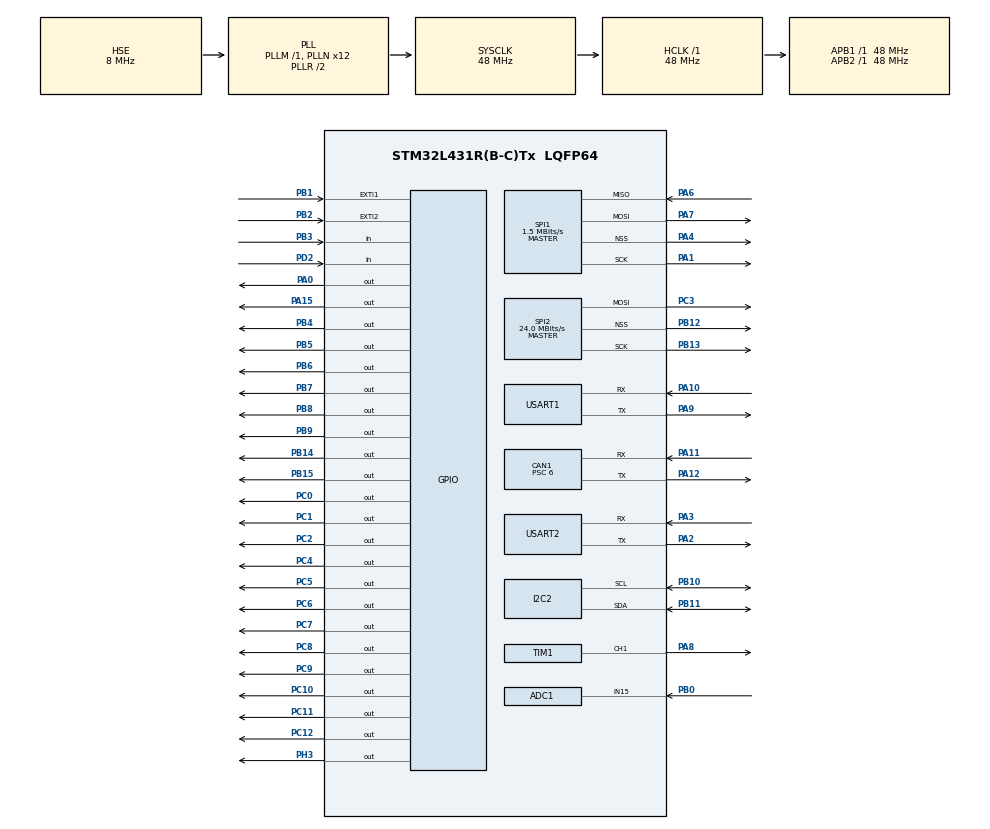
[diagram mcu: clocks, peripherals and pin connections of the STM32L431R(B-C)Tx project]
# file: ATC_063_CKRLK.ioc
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ADC1.Channel-1\#ChannelRegularConversion=ADC_CHANNEL_15
ADC1.NbrOfConversionFlag=1
ADC1.OffsetNumber-1\#ChannelRegularConversion=ADC_OFFSET_NONE
ADC1.Rank-1\#ChannelRegularConversion=1
ADC1.SamplingTime-1\#ChannelRegularConversion=ADC_SAMPLETIME_2CYCLES_5
ADC1.master=1
CAN1.BS1=CAN_BS1_13TQ
CAN1.BS2=CAN_BS2_2TQ
CAN1.CalculateBaudRate=500000
CAN1.CalculateTimeBit=2000
CAN1.CalculateTimeQuantum=125.0
CAN1.Prescaler=6
Dma.I2C2_RX.1.Direction=DMA_PERIPH_TO_MEMORY
Dma.I2C2_RX.1.Instance=DMA1_Channel5
Dma.I2C2_RX.1.MemDataAlignment=DMA_MDATAALIGN_BYTE
Dma.I2C2_RX.1.MemInc=DMA_MINC_ENABLE
Dma.I2C2_RX.1.Mode=DMA_NORMAL
Dma.I2C2_RX.1.PeriphDataAlignment=DMA_PDATAALIGN_BYTE
Dma.I2C2_RX.1.PeriphInc=DMA_PINC_DISABLE
Dma.I2C2_RX.1.Priority=DMA_PRIORITY_LOW
Dma.I2C2_TX.0.Direction=DMA_MEMORY_TO_PERIPH
Dma.I2C2_TX.0.Instance=DMA1_Channel4
Dma.I2C2_TX.0.MemDataAlignment=DMA_MDATAALIGN_BYTE
Dma.I2C2_TX.0.MemInc=DMA_MINC_ENABLE
Dma.I2C2_TX.0.Mode=DMA_NORMAL
Dma.I2C2_TX.0.PeriphDataAlignment=DMA_PDATAALIGN_BYTE
Dma.I2C2_TX.0.PeriphInc=DMA_PINC_DISABLE
Dma.I2C2_TX.0.Priority=DMA_PRIORITY_LOW
Dma.Request0=I2C2_TX
Dma.Request1=I2C2_RX
Dma.Request2=SPI1_RX
Dma.Request3=SPI1_TX
Dma.Request4=USART1_RX
Dma.Request5=USART1_TX
Dma.Request6=USART2_RX
Dma.Request7=USART2_TX
Dma.SPI1_RX.2.Direction=DMA_PERIPH_TO_MEMORY
Dma.SPI1_RX.2.Instance=DMA1_Channel2
Dma.SPI1_RX.2.MemDataAlignment=DMA_MDATAALIGN_BYTE
Dma.SPI1_RX.2.MemInc=DMA_MINC_ENABLE
Dma.SPI1_RX.2.Mode=DMA_NORMAL
Dma.SPI1_RX.2.PeriphDataAlignment=DMA_PDATAALIGN_BYTE
Dma.SPI1_RX.2.PeriphInc=DMA_PINC_DISABLE
Dma.SPI1_RX.2.Priority=DMA_PRIORITY_LOW
Dma.SPI1_TX.3.Direction=DMA_MEMORY_TO_PERIPH
Dma.SPI1_TX.3.Instance=DMA1_Channel3
Dma.SPI1_TX.3.MemDataAlignment=DMA_MDATAALIGN_BYTE
Dma.SPI1_TX.3.MemInc=DMA_MINC_ENABLE
Dma.SPI1_TX.3.Mode=DMA_NORMAL
Dma.SPI1_TX.3.PeriphDataAlignment=DMA_PDATAALIGN_BYTE
Dma.SPI1_TX.3.PeriphInc=DMA_PINC_DISABLE
Dma.SPI1_TX.3.Priority=DMA_PRIORITY_LOW
Dma.USART1_RX.4.Direction=DMA_PERIPH_TO_MEMORY
Dma.USART1_RX.4.Instance=DMA2_Channel7
Dma.USART1_RX.4.MemDataAlignment=DMA_MDATAALIGN_BYTE
Dma.USART1_RX.4.MemInc=DMA_MINC_ENABLE
Dma.USART1_RX.4.Mode=DMA_NORMAL
Dma.USART1_RX.4.PeriphDataAlignment=DMA_PDATAALIGN_BYTE
Dma.USART1_RX.4.PeriphInc=DMA_PINC_DISABLE
Dma.USART1_RX.4.Priority=DMA_PRIORITY_LOW
Dma.USART1_TX.5.Direction=DMA_MEMORY_TO_PERIPH
Dma.USART1_TX.5.Instance=DMA2_Channel6
Dma.USART1_TX.5.MemDataAlignment=DMA_MDATAALIGN_BYTE
Dma.USART1_TX.5.MemInc=DMA_MINC_ENABLE
Dma.USART1_TX.5.Mode=DMA_NORMAL
Dma.USART1_TX.5.PeriphDataAlignment=DMA_PDATAALIGN_BYTE
Dma.USART1_TX.5.PeriphInc=DMA_PINC_DISABLE
Dma.USART1_TX.5.Priority=DMA_PRIORITY_LOW
Dma.USART2_RX.6.Direction=DMA_PERIPH_TO_MEMORY
Dma.USART2_RX.6.Instance=DMA1_Channel6
Dma.USART2_RX.6.MemDataAlignment=DMA_MDATAALIGN_BYTE
Dma.USART2_RX.6.MemInc=DMA_MINC_ENABLE
Dma.USART2_RX.6.Mode=DMA_NORMAL
Dma.USART2_RX.6.PeriphDataAlignment=DMA_PDATAALIGN_BYTE
Dma.USART2_RX.6.PeriphInc=DMA_PINC_DISABLE
Dma.USART2_RX.6.Priority=DMA_PRIORITY_LOW
Dma.USART2_TX.7.Direction=DMA_MEMORY_TO_PERIPH
Dma.USART2_TX.7.Instance=DMA1_Channel7
Dma.USART2_TX.7.MemDataAlignment=DMA_MDATAALIGN_BYTE
Dma.USART2_TX.7.MemInc=DMA_MINC_ENABLE
Dma.USART2_TX.7.Mode=DMA_NORMAL
Dma.USART2_TX.7.PeriphDataAlignment=DMA_PDATAALIGN_BYTE
Dma.USART2_TX.7.PeriphInc=DMA_PINC_DISABLE
Dma.USART2_TX.7.Priority=DMA_PRIORITY_LOW
I2C2.Timing=0x20303E5D
LPTIM1.ClockPrescaler=LPTIM_PRESCALER_DIV128
Mcu.Family=STM32L4
Mcu.Name=STM32L431R(B-C)Tx
Mcu.Package=LQFP64
NVIC.CAN1_RX0_IRQn=true\:0\:0\:false\:false\:true\:true\:true\:true
NVIC.CAN1_SCE_IRQn=true\:0\:0\:false\:false\:true\:true\:true\:true
NVIC.DMA1_Channel2_IRQn=true\:0\:0\:false\:false\:true\:false\:true\:true
NVIC.DMA1_Channel3_IRQn=true\:0\:0\:false\:false\:true\:false\:true\:true
NVIC.DMA1_Channel4_IRQn=true\:0\:0\:false\:false\:true\:false\:true\:true
NVIC.DMA1_Channel5_IRQn=true\:0\:0\:false\:false\:true\:false\:true\:true
NVIC.DMA1_Channel6_IRQn=true\:0\:0\:false\:false\:true\:false\:true\:true
NVIC.DMA1_Channel7_IRQn=true\:0\:0\:false\:false\:true\:false\:true\:true
NVIC.DMA2_Channel6_IRQn=true\:0\:0\:false\:false\:true\:false\:true\:true
NVIC.DMA2_Channel7_IRQn=true\:0\:0\:false\:false\:true\:false\:true\:true
NVIC.EXTI1_IRQn=true\:0\:0\:false\:false\:true\:true\:true\:true
NVIC.EXTI2_IRQn=true\:0\:0\:false\:false\:true\:true\:true\:true
NVIC.I2C2_EV_IRQn=true\:0\:0\:false\:false\:true\:true\:true\:true
NVIC.LPTIM1_IRQn=true\:0\:0\:false\:false\:true\:true\:true\:true
NVIC.PriorityGroup=NVIC_PRIORITYGROUP_4
PA0.Signal=GPIO_Output
PA1.Mode=Full_Duplex_Master
PA1.Signal=SPI1_SCK
PA10.Mode=Asynchronous
PA10.Signal=USART1_RX
PA11.Mode=CAN_Activate
PA11.Signal=CAN1_RX
PA12.Mode=CAN_Activate
PA12.Signal=CAN1_TX
PA13\ (JTMS-SWDIO).Mode=Serial_Wire
PA13\ (JTMS-SWDIO).Signal=SYS_JTMS-SWDIO
PA14\ (JTCK-SWCLK).Mode=Serial_Wire
PA14\ (JTCK-SWCLK).Signal=SYS_JTCK-SWCLK
PA15\ (JTDI).Signal=GPIO_Output
PA2.Mode=Asynchronous
PA2.Signal=USART2_TX
PA3.Mode=Asynchronous
PA3.Signal=USART2_RX
PA4.Mode=NSS_Signal_Hard_Output
PA4.Signal=SPI1_NSS
PA5.Signal=ADCx_IN10
PA6.Mode=Full_Duplex_Master
PA6.Signal=SPI1_MISO
PA7.Mode=Full_Duplex_Master
PA7.Signal=SPI1_MOSI
PA8.Signal=S_TIM1_CH1
PA9.Mode=Asynchronous
PA9.Signal=USART1_TX
PB0.Signal=ADCx_IN15
PB1.Signal=GPXTI1
PB10.Mode=I2C
PB10.Signal=I2C2_SCL
PB11.Mode=I2C
PB11.Signal=I2C2_SDA
PB12.Mode=NSS_Signal_Hard_Output
PB12.Signal=SPI2_NSS
PB13.Mode=TX_Only_Simplex_Unidirect_Master
PB13.Signal=SPI2_SCK
PB14.Signal=GPIO_Output
PB15.Signal=GPIO_Output
PB2.Signal=GPXTI2
PB3\ (JTDO-TRACESWO).Signal=GPIO_Input
PB4\ (NJTRST).Signal=GPIO_Output
PB5.Signal=GPIO_Output
PB6.Signal=GPIO_Output
PB7.Signal=GPIO_Output
PB8.Signal=GPIO_Output
PB9.Signal=GPIO_Output
PC0.Signal=GPIO_Output
PC1.Signal=GPIO_Output
PC10.Signal=GPIO_Output
PC11.Signal=GPIO_Output
PC12.Signal=GPIO_Output
PC14-OSC32_IN\ (PC14).Mode=LSE-External-Oscillator
PC14-OSC32_IN\ (PC14).Signal=RCC_OSC32_IN
PC15-OSC32_OUT\ (PC15).Mode=LSE-External-Oscillator
PC15-OSC32_OUT\ (PC15).Signal=RCC_OSC32_OUT
PC2.Signal=GPIO_Output
PC3.Mode=TX_Only_Simplex_Unidirect_Master
PC3.Signal=SPI2_MOSI
PC4.Signal=GPIO_Output
PC5.Signal=GPIO_Output
PC6.Signal=GPIO_Output
PC7.Signal=GPIO_Output
PC8.Signal=GPIO_Output
PC9.Signal=GPIO_Output
PD2.Signal=GPIO_Input
PH0-OSC_IN\ (PH0).Mode=HSE-External-Oscillator
PH0-OSC_IN\ (PH0).Signal=RCC_OSC_IN
PH1-OSC_OUT\ (PH1).Mode=HSE-External-Oscillator
PH1-OSC_OUT\ (PH1).Signal=RCC_OSC_OUT
PH3-BOOT0.Signal=GPIO_Output
ProjectManager.HeapSize=0x200
ProjectManager.StackSize=0x400
ProjectManager.TargetToolchain=STM32CubeIDE
RCC.ADCFreq_Value=32000000
RCC.AHBFreq_Value=48000000
RCC.APB1Freq_Value=48000000
RCC.APB1TimFreq_Value=48000000
RCC.APB2Freq_Value=48000000
RCC.APB2TimFreq_Value=48000000
RCC.CortexFreq_Value=48000000
RCC.EnbaleCSS=true
RCC.HCLKFreq_Value=48000000
RCC.HSE_Timout=100
RCC.HSE_VALUE=8000000
RCC.HSI48_VALUE=48000000
RCC.HSI_VALUE=16000000
RCC.LSE_Timout=5000
RCC.MSI_VALUE=4000000
RCC.PLLN=12
RCC.PLLSourceVirtual=RCC_PLLSOURCE_HSE
RCC.SYSCLKFreq_VALUE=48000000
RCC.SYSCLKSource=RCC_SYSCLKSOURCE_PLLCLK
RCC.VCOOutputFreq_Value=96000000
SH.ADCx_IN10.0=ADC1_IN10
SH.ADCx_IN15.0=ADC1_IN15,IN15-Single-Ended
SH.S_TIM1_CH1.0=TIM1_CH1,Output Compare1 CH1
SPI1.BaudRatePrescaler=SPI_BAUDRATEPRESCALER_32
SPI1.CLKPhase=SPI_PHASE_2EDGE
SPI1.CalculateBaudRate=1.5 MBits/s
SPI1.DataSize=SPI_DATASIZE_8BIT
SPI1.Direction=SPI_DIRECTION_2LINES
SPI1.Mode=SPI_MODE_MASTER
SPI1.VirtualNSS=VM_NSSHARD
SPI1.VirtualType=VM_MASTER
SPI2.CLKPhase=SPI_PHASE_2EDGE
SPI2.CalculateBaudRate=24.0 MBits/s
SPI2.DataSize=SPI_DATASIZE_8BIT
SPI2.Direction=SPI_DIRECTION_2LINES
SPI2.Mode=SPI_MODE_MASTER
SPI2.VirtualNSS=VM_NSSHARD
SPI2.VirtualType=VM_MASTER
TIM1.Channel-Output\ Compare1\ CH1=TIM_CHANNEL_1
USART1.VirtualMode-Asynchronous=VM_ASYNC
USART2.VirtualMode-Asynchronous=VM_ASYNC
VP_ADC1_TempSens_Input.Mode=IN-TempSens
VP_ADC1_Vbat_Input.Mode=IN-Vbat
VP_CRC_VS_CRC.Mode=CRC_Activate
VP_LPTIM1_VS_LPTIM_counterModeInternalClock.Mode=Counts__internal_clock_event_00
VP_RTC_VS_RTC_Activate.Mode=RTC_Enabled
VP_RTC_VS_RTC_Calendar.Mode=RTC_Calendar
VP_TIM1_VS_ClockSourceINT.Mode=Internal
VP_TIM1_VS_ClockSourceITR.Mode=TriggerSource_ITR0
board=custom

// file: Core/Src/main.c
/* USER CODE BEGIN Header */
/**
  ******************************************************************************
  * @file           : main.c
  * @brief          : Main program body
  ******************************************************************************
  * @attention
  *
  * Copyright (c) 2022 STMicroelectronics.
  * All rights reserved.
  *
  * This software is licensed under terms that can be found in the LICENSE file
  * in the root directory of this software component.
  * If no LICENSE file comes with this software, it is provided AS-IS.
  *
  ******************************************************************************
  */
/* USER CODE END Header */
#include "main.h"

/* USER CODE BEGIN Includes */
#include "system_app/mainThread.h"
/* USER CODE END Includes */

ADC_HandleTypeDef hadc1;

CAN_HandleTypeDef hcan1;

CRC_HandleTypeDef hcrc;

I2C_HandleTypeDef hi2c2;
DMA_HandleTypeDef hdma_i2c2_tx;
DMA_HandleTypeDef hdma_i2c2_rx;

LPTIM_HandleTypeDef hlptim1;

RTC_HandleTypeDef hrtc;

SPI_HandleTypeDef hspi1;
SPI_HandleTypeDef hspi2;
DMA_HandleTypeDef hdma_spi1_rx;
DMA_HandleTypeDef hdma_spi1_tx;

TIM_HandleTypeDef htim1;

UART_HandleTypeDef huart1;
UART_HandleTypeDef huart2;
DMA_HandleTypeDef hdma_usart1_rx;
DMA_HandleTypeDef hdma_usart1_tx;
DMA_HandleTypeDef hdma_usart2_rx;
DMA_HandleTypeDef hdma_usart2_tx;

void SystemClock_Config(void);
static void MX_GPIO_Init(void);
static void MX_DMA_Init(void);
static void MX_RTC_Init(void);
static void MX_ADC1_Init(void);
static void MX_CAN1_Init(void);
static void MX_I2C2_Init(void);
static void MX_SPI1_Init(void);
static void MX_SPI2_Init(void);
static void MX_USART1_UART_Init(void);
static void MX_USART2_UART_Init(void);
static void MX_LPTIM1_Init(void);
static void MX_CRC_Init(void);
static void MX_TIM1_Init(void);

int main(void)
{

  /* MCU Configuration--------------------------------------------------------*/

  /* Reset of all peripherals, Initializes the Flash interface and the Systick. */
  HAL_Init();

  /* Configure the system clock */
  SystemClock_Config();

  /* Initialize all configured peripherals */
  MX_GPIO_Init();
  MX_DMA_Init();
  MX_RTC_Init();
  MX_ADC1_Init();
  MX_CAN1_Init();
  MX_I2C2_Init();
  MX_SPI1_Init();
  MX_SPI2_Init();
  MX_USART1_UART_Init();
  MX_USART2_UART_Init();
  MX_LPTIM1_Init();
  MX_CRC_Init();
  MX_TIM1_Init();
  /* USER CODE BEGIN 2 */
  MainThreadProcessInit();
  /* USER CODE END 2 */

  /* Infinite loop */
  while (1)
  {

  }
}

void SystemClock_Config(void)
{
  RCC_OscInitTypeDef RCC_OscInitStruct = {0};
  RCC_ClkInitTypeDef RCC_ClkInitStruct = {0};

  /** Configure the main internal regulator output voltage
  */
  if (HAL_PWREx_ControlVoltageScaling(PWR_REGULATOR_VOLTAGE_SCALE1) != HAL_OK)
  {
    Error_Handler();
  }
  /** Initializes the RCC Oscillators according to the specified parameters
  * in the RCC_OscInitTypeDef structure.
  */
  RCC_OscInitStruct.OscillatorType = RCC_OSCILLATORTYPE_LSI|RCC_OSCILLATORTYPE_HSE;
  RCC_OscInitStruct.HSEState = RCC_HSE_ON;
  RCC_OscInitStruct.LSIState = RCC_LSI_ON;
  RCC_OscInitStruct.PLL.PLLState = RCC_PLL_ON;
  RCC_OscInitStruct.PLL.PLLSource = RCC_PLLSOURCE_HSE;
  RCC_OscInitStruct.PLL.PLLM = 1;
  RCC_OscInitStruct.PLL.PLLN = 12;
  RCC_OscInitStruct.PLL.PLLP = RCC_PLLP_DIV7;
  RCC_OscInitStruct.PLL.PLLQ = RCC_PLLQ_DIV2;
  RCC_OscInitStruct.PLL.PLLR = RCC_PLLR_DIV2;
  if (HAL_RCC_OscConfig(&RCC_OscInitStruct) != HAL_OK)
  {
    Error_Handler();
  }
  /** Initializes the CPU, AHB and APB buses clocks
  */
  RCC_ClkInitStruct.ClockType = RCC_CLOCKTYPE_HCLK|RCC_CLOCKTYPE_SYSCLK
                              |RCC_CLOCKTYPE_PCLK1|RCC_CLOCKTYPE_PCLK2;
  RCC_ClkInitStruct.SYSCLKSource = RCC_SYSCLKSOURCE_PLLCLK;
  RCC_ClkInitStruct.AHBCLKDivider = RCC_SYSCLK_DIV1;
  RCC_ClkInitStruct.APB1CLKDivider = RCC_HCLK_DIV1;
  RCC_ClkInitStruct.APB2CLKDivider = RCC_HCLK_DIV1;

  if (HAL_RCC_ClockConfig(&RCC_ClkInitStruct, FLASH_LATENCY_2) != HAL_OK)
  {
    Error_Handler();
  }
  /** Enables the Clock Security System
  */
  HAL_RCC_EnableCSS();
}

static void MX_ADC1_Init(void)
{

  ADC_ChannelConfTypeDef sConfig = {0};

  /** Common config
  */
  hadc1.Instance = ADC1;
  hadc1.Init.ClockPrescaler = ADC_CLOCK_ASYNC_DIV1;
  hadc1.Init.Resolution = ADC_RESOLUTION_12B;
  hadc1.Init.DataAlign = ADC_DATAALIGN_RIGHT;
  hadc1.Init.ScanConvMode = ADC_SCAN_DISABLE;
  hadc1.Init.EOCSelection = ADC_EOC_SINGLE_CONV;
  hadc1.Init.LowPowerAutoWait = DISABLE;
  hadc1.Init.ContinuousConvMode = DISABLE;
  hadc1.Init.NbrOfConversion = 1;
  hadc1.Init.DiscontinuousConvMode = DISABLE;
  hadc1.Init.ExternalTrigConv = ADC_SOFTWARE_START;
  hadc1.Init.ExternalTrigConvEdge = ADC_EXTERNALTRIGCONVEDGE_NONE;
  hadc1.Init.DMAContinuousRequests = DISABLE;
  hadc1.Init.Overrun = ADC_OVR_DATA_PRESERVED;
  hadc1.Init.OversamplingMode = DISABLE;
  if (HAL_ADC_Init(&hadc1) != HAL_OK)
  {
    Error_Handler();
  }
  /** Configure Regular Channel
  */
  sConfig.Channel = ADC_CHANNEL_15;
  sConfig.Rank = ADC_REGULAR_RANK_1;
  sConfig.SamplingTime = ADC_SAMPLETIME_2CYCLES_5;
  sConfig.SingleDiff = ADC_SINGLE_ENDED;
  sConfig.OffsetNumber = ADC_OFFSET_NONE;
  sConfig.Offset = 0;
  if (HAL_ADC_ConfigChannel(&hadc1, &sConfig) != HAL_OK)
  {
    Error_Handler();
  }

}

static void MX_CAN1_Init(void)
{

  hcan1.Instance = CAN1;
  hcan1.Init.Prescaler = 6;
  hcan1.Init.Mode = CAN_MODE_NORMAL;
  hcan1.Init.SyncJumpWidth = CAN_SJW_1TQ;
  hcan1.Init.TimeSeg1 = CAN_BS1_13TQ;
  hcan1.Init.TimeSeg2 = CAN_BS2_2TQ;
  hcan1.Init.TimeTriggeredMode = DISABLE;
  hcan1.Init.AutoBusOff = DISABLE;
  hcan1.Init.AutoWakeUp = DISABLE;
  hcan1.Init.AutoRetransmission = DISABLE;
  hcan1.Init.ReceiveFifoLocked = DISABLE;
  hcan1.Init.TransmitFifoPriority = DISABLE;
  if (HAL_CAN_Init(&hcan1) != HAL_OK)
  {
    Error_Handler();
  }

}

static void MX_CRC_Init(void)
{

  hcrc.Instance = CRC;
  hcrc.Init.DefaultPolynomialUse = DEFAULT_POLYNOMIAL_ENABLE;
  hcrc.Init.DefaultInitValueUse = DEFAULT_INIT_VALUE_ENABLE;
  hcrc.Init.InputDataInversionMode = CRC_INPUTDATA_INVERSION_NONE;
  hcrc.Init.OutputDataInversionMode = CRC_OUTPUTDATA_INVERSION_DISABLE;
  hcrc.InputDataFormat = CRC_INPUTDATA_FORMAT_BYTES;
  if (HAL_CRC_Init(&hcrc) != HAL_OK)
  {
    Error_Handler();
  }

}

static void MX_I2C2_Init(void)
{

  hi2c2.Instance = I2C2;
  hi2c2.Init.Timing = 0x20303E5D;
  hi2c2.Init.OwnAddress1 = 0;
  hi2c2.Init.AddressingMode = I2C_ADDRESSINGMODE_7BIT;
  hi2c2.Init.DualAddressMode = I2C_DUALADDRESS_DISABLE;
  hi2c2.Init.OwnAddress2 = 0;
  hi2c2.Init.OwnAddress2Masks = I2C_OA2_NOMASK;
  hi2c2.Init.GeneralCallMode = I2C_GENERALCALL_DISABLE;
  hi2c2.Init.NoStretchMode = I2C_NOSTRETCH_DISABLE;
  if (HAL_I2C_Init(&hi2c2) != HAL_OK)
  {
    Error_Handler();
  }
  /** Configure Analogue filter
  */
  if (HAL_I2CEx_ConfigAnalogFilter(&hi2c2, I2C_ANALOGFILTER_ENABLE) != HAL_OK)
  {
    Error_Handler();
  }
  /** Configure Digital filter
  */
  if (HAL_I2CEx_ConfigDigitalFilter(&hi2c2, 0) != HAL_OK)
  {
    Error_Handler();
  }

}

static void MX_LPTIM1_Init(void)
{

  hlptim1.Instance = LPTIM1;
  hlptim1.Init.Clock.Source = LPTIM_CLOCKSOURCE_APBCLOCK_LPOSC;
  hlptim1.Init.Clock.Prescaler = LPTIM_PRESCALER_DIV128;
  hlptim1.Init.Trigger.Source = LPTIM_TRIGSOURCE_SOFTWARE;
  hlptim1.Init.OutputPolarity = LPTIM_OUTPUTPOLARITY_HIGH;
  hlptim1.Init.UpdateMode = LPTIM_UPDATE_IMMEDIATE;
  hlptim1.Init.CounterSource = LPTIM_COUNTERSOURCE_INTERNAL;
  hlptim1.Init.Input1Source = LPTIM_INPUT1SOURCE_GPIO;
  hlptim1.Init.Input2Source = LPTIM_INPUT2SOURCE_GPIO;
  if (HAL_LPTIM_Init(&hlptim1) != HAL_OK)
  {
    Error_Handler();
  }

}

static void MX_RTC_Init(void)
{

  RTC_TimeTypeDef sTime = {0};
  RTC_DateTypeDef sDate = {0};

  /** Initialize RTC Only
  */
  hrtc.Instance = RTC;
  hrtc.Init.HourFormat = RTC_HOURFORMAT_24;
  hrtc.Init.AsynchPrediv = 127;
  hrtc.Init.SynchPrediv = 255;
  hrtc.Init.OutPut = RTC_OUTPUT_DISABLE;
  hrtc.Init.OutPutRemap = RTC_OUTPUT_REMAP_NONE;
  hrtc.Init.OutPutPolarity = RTC_OUTPUT_POLARITY_HIGH;
  hrtc.Init.OutPutType = RTC_OUTPUT_TYPE_OPENDRAIN;
  if (HAL_RTC_Init(&hrtc) != HAL_OK)
  {
    Error_Handler();
  }

  /** Initialize RTC and set the Time and Date
  */
  sTime.Hours = 0x0;
  sTime.Minutes = 0x0;
  sTime.Seconds = 0x0;
  sTime.DayLightSaving = RTC_DAYLIGHTSAVING_NONE;
  sTime.StoreOperation = RTC_STOREOPERATION_RESET;
  if (HAL_RTC_SetTime(&hrtc, &sTime, RTC_FORMAT_BCD) != HAL_OK)
  {
    Error_Handler();
  }
  sDate.WeekDay = RTC_WEEKDAY_MONDAY;
  sDate.Month = RTC_MONTH_JANUARY;
  sDate.Date = 0x1;
  sDate.Year = 0x0;

  if (HAL_RTC_SetDate(&hrtc, &sDate, RTC_FORMAT_BCD) != HAL_OK)
  {
    Error_Handler();
  }

}

static void MX_SPI1_Init(void)
{

  /* SPI1 parameter configuration*/
  hspi1.Instance = SPI1;
  hspi1.Init.Mode = SPI_MODE_MASTER;
  hspi1.Init.Direction = SPI_DIRECTION_2LINES;
  hspi1.Init.DataSize = SPI_DATASIZE_8BIT;
  hspi1.Init.CLKPolarity = SPI_POLARITY_LOW;
  hspi1.Init.CLKPhase = SPI_PHASE_2EDGE;
  hspi1.Init.NSS = SPI_NSS_HARD_OUTPUT;
  hspi1.Init.BaudRatePrescaler = SPI_BAUDRATEPRESCALER_32;
  hspi1.Init.FirstBit = SPI_FIRSTBIT_MSB;
  hspi1.Init.TIMode = SPI_TIMODE_DISABLE;
  hspi1.Init.CRCCalculation = SPI_CRCCALCULATION_DISABLE;
  hspi1.Init.CRCPolynomial = 7;
  hspi1.Init.CRCLength = SPI_CRC_LENGTH_DATASIZE;
  hspi1.Init.NSSPMode = SPI_NSS_PULSE_DISABLE;
  if (HAL_SPI_Init(&hspi1) != HAL_OK)
  {
    Error_Handler();
  }

}

static void MX_SPI2_Init(void)
{

  /* SPI2 parameter configuration*/
  hspi2.Instance = SPI2;
  hspi2.Init.Mode = SPI_MODE_MASTER;
  hspi2.Init.Direction = SPI_DIRECTION_2LINES;
  hspi2.Init.DataSize = SPI_DATASIZE_8BIT;
  hspi2.Init.CLKPolarity = SPI_POLARITY_LOW;
  hspi2.Init.CLKPhase = SPI_PHASE_2EDGE;
  hspi2.Init.NSS = SPI_NSS_HARD_OUTPUT;
  hspi2.Init.BaudRatePrescaler = SPI_BAUDRATEPRESCALER_2;
  hspi2.Init.FirstBit = SPI_FIRSTBIT_MSB;
  hspi2.Init.TIMode = SPI_TIMODE_DISABLE;
  hspi2.Init.CRCCalculation = SPI_CRCCALCULATION_DISABLE;
  hspi2.Init.CRCPolynomial = 7;
  hspi2.Init.CRCLength = SPI_CRC_LENGTH_DATASIZE;
  hspi2.Init.NSSPMode = SPI_NSS_PULSE_DISABLE;
  if (HAL_SPI_Init(&hspi2) != HAL_OK)
  {
    Error_Handler();
  }

}

static void MX_TIM1_Init(void)
{

  TIM_ClockConfigTypeDef sClockSourceConfig = {0};
  TIM_SlaveConfigTypeDef sSlaveConfig = {0};
  TIM_MasterConfigTypeDef sMasterConfig = {0};
  TIM_OC_InitTypeDef sConfigOC = {0};
  TIM_BreakDeadTimeConfigTypeDef sBreakDeadTimeConfig = {0};

  htim1.Instance = TIM1;
  htim1.Init.Prescaler = 0;
  htim1.Init.CounterMode = TIM_COUNTERMODE_UP;
  htim1.Init.Period = 65535;
  htim1.Init.ClockDivision = TIM_CLOCKDIVISION_DIV1;
  htim1.Init.RepetitionCounter = 0;
  htim1.Init.AutoReloadPreload = TIM_AUTORELOAD_PRELOAD_DISABLE;
  if (HAL_TIM_Base_Init(&htim1) != HAL_OK)
  {
    Error_Handler();
  }
  sClockSourceConfig.ClockSource = TIM_CLOCKSOURCE_INTERNAL;
  if (HAL_TIM_ConfigClockSource(&htim1, &sClockSourceConfig) != HAL_OK)
  {
    Error_Handler();
  }
  if (HAL_TIM_OC_Init(&htim1) != HAL_OK)
  {
    Error_Handler();
  }
  sSlaveConfig.SlaveMode = TIM_SLAVEMODE_DISABLE;
  sSlaveConfig.InputTrigger = TIM_TS_ITR0;
  if (HAL_TIM_SlaveConfigSynchro(&htim1, &sSlaveConfig) != HAL_OK)
  {
    Error_Handler();
  }
  sMasterConfig.MasterOutputTrigger = TIM_TRGO_RESET;
  sMasterConfig.MasterOutputTrigger2 = TIM_TRGO2_RESET;
  sMasterConfig.MasterSlaveMode = TIM_MASTERSLAVEMODE_DISABLE;
  if (HAL_TIMEx_MasterConfigSynchronization(&htim1, &sMasterConfig) != HAL_OK)
  {
    Error_Handler();
  }
  sConfigOC.OCMode = TIM_OCMODE_TIMING;
  sConfigOC.Pulse = 0;
  sConfigOC.OCPolarity = TIM_OCPOLARITY_HIGH;
  sConfigOC.OCNPolarity = TIM_OCNPOLARITY_HIGH;
  sConfigOC.OCFastMode = TIM_OCFAST_DISABLE;
  sConfigOC.OCIdleState = TIM_OCIDLESTATE_RESET;
  sConfigOC.OCNIdleState = TIM_OCNIDLESTATE_RESET;
  if (HAL_TIM_OC_ConfigChannel(&htim1, &sConfigOC, TIM_CHANNEL_1) != HAL_OK)
  {
    Error_Handler();
  }
  sBreakDeadTimeConfig.OffStateRunMode = TIM_OSSR_DISABLE;
  sBreakDeadTimeConfig.OffStateIDLEMode = TIM_OSSI_DISABLE;
  sBreakDeadTimeConfig.LockLevel = TIM_LOCKLEVEL_OFF;
  sBreakDeadTimeConfig.DeadTime = 0;
  sBreakDeadTimeConfig.BreakState = TIM_BREAK_DISABLE;
  sBreakDeadTimeConfig.BreakPolarity = TIM_BREAKPOLARITY_HIGH;
  sBreakDeadTimeConfig.BreakFilter = 0;
  sBreakDeadTimeConfig.Break2State = TIM_BREAK2_DISABLE;
  sBreakDeadTimeConfig.Break2Polarity = TIM_BREAK2POLARITY_HIGH;
  sBreakDeadTimeConfig.Break2Filter = 0;
  sBreakDeadTimeConfig.AutomaticOutput = TIM_AUTOMATICOUTPUT_DISABLE;
  if (HAL_TIMEx_ConfigBreakDeadTime(&htim1, &sBreakDeadTimeConfig) != HAL_OK)
  {
    Error_Handler();
  }
  HAL_TIM_MspPostInit(&htim1);

}

static void MX_USART1_UART_Init(void)
{

  huart1.Instance = USART1;
  huart1.Init.BaudRate = 115200;
  huart1.Init.WordLength = UART_WORDLENGTH_8B;
  huart1.Init.StopBits = UART_STOPBITS_1;
  huart1.Init.Parity = UART_PARITY_NONE;
  huart1.Init.Mode = UART_MODE_TX_RX;
  huart1.Init.HwFlowCtl = UART_HWCONTROL_NONE;
  huart1.Init.OverSampling = UART_OVERSAMPLING_16;
  huart1.Init.OneBitSampling = UART_ONE_BIT_SAMPLE_DISABLE;
  huart1.AdvancedInit.AdvFeatureInit = UART_ADVFEATURE_NO_INIT;
  if (HAL_UART_Init(&huart1) != HAL_OK)
  {
    Error_Handler();
  }

}

static void MX_USART2_UART_Init(void)
{

  huart2.Instance = USART2;
  huart2.Init.BaudRate = 115200;
  huart2.Init.WordLength = UART_WORDLENGTH_8B;
  huart2.Init.StopBits = UART_STOPBITS_1;
  huart2.Init.Parity = UART_PARITY_NONE;
  huart2.Init.Mode = UART_MODE_TX_RX;
  huart2.Init.HwFlowCtl = UART_HWCONTROL_NONE;
  huart2.Init.OverSampling = UART_OVERSAMPLING_16;
  huart2.Init.OneBitSampling = UART_ONE_BIT_SAMPLE_DISABLE;
  huart2.AdvancedInit.AdvFeatureInit = UART_ADVFEATURE_NO_INIT;
  if (HAL_UART_Init(&huart2) != HAL_OK)
  {
    Error_Handler();
  }

}

static void MX_DMA_Init(void)
{

  /* DMA controller clock enable */
  __HAL_RCC_DMA1_CLK_ENABLE();
  __HAL_RCC_DMA2_CLK_ENABLE();

  /* DMA interrupt init */
  /* DMA1_Channel2_IRQn interrupt configuration */
  HAL_NVIC_SetPriority(DMA1_Channel2_IRQn, 0, 0);
  HAL_NVIC_EnableIRQ(DMA1_Channel2_IRQn);
  /* DMA1_Channel3_IRQn interrupt configuration */
  HAL_NVIC_SetPriority(DMA1_Channel3_IRQn, 0, 0);
  HAL_NVIC_EnableIRQ(DMA1_Channel3_IRQn);
  /* DMA1_Channel4_IRQn interrupt configuration */
  HAL_NVIC_SetPriority(DMA1_Channel4_IRQn, 0, 0);
  HAL_NVIC_EnableIRQ(DMA1_Channel4_IRQn);
  /* DMA1_Channel5_IRQn interrupt configuration */
  HAL_NVIC_SetPriority(DMA1_Channel5_IRQn, 0, 0);
  HAL_NVIC_EnableIRQ(DMA1_Channel5_IRQn);
  /* DMA1_Channel6_IRQn interrupt configuration */
  HAL_NVIC_SetPriority(DMA1_Channel6_IRQn, 0, 0);
  HAL_NVIC_EnableIRQ(DMA1_Channel6_IRQn);
  /* DMA1_Channel7_IRQn interrupt configuration */
  HAL_NVIC_SetPriority(DMA1_Channel7_IRQn, 0, 0);
  HAL_NVIC_EnableIRQ(DMA1_Channel7_IRQn);
  /* DMA2_Channel6_IRQn interrupt configuration */
  HAL_NVIC_SetPriority(DMA2_Channel6_IRQn, 0, 0);
  HAL_NVIC_EnableIRQ(DMA2_Channel6_IRQn);
  /* DMA2_Channel7_IRQn interrupt configuration */
  HAL_NVIC_SetPriority(DMA2_Channel7_IRQn, 0, 0);
  HAL_NVIC_EnableIRQ(DMA2_Channel7_IRQn);

}

static void MX_GPIO_Init(void)
{
  GPIO_InitTypeDef GPIO_InitStruct = {0};

  /* GPIO Ports Clock Enable */
  __HAL_RCC_GPIOC_CLK_ENABLE();
  __HAL_RCC_GPIOH_CLK_ENABLE();
  __HAL_RCC_GPIOA_CLK_ENABLE();
  __HAL_RCC_GPIOB_CLK_ENABLE();
  __HAL_RCC_GPIOD_CLK_ENABLE();

  /*Configure GPIO pin Output Level */
  HAL_GPIO_WritePin(GPIOC, GPIO_PIN_0|GPIO_PIN_1|GPIO_PIN_2|GPIO_PIN_4
                          |GPIO_PIN_5|GPIO_PIN_6|GPIO_PIN_7|GPIO_PIN_8
                          |GPIO_PIN_9|GPIO_PIN_10|GPIO_PIN_11|GPIO_PIN_12, GPIO_PIN_RESET);

  /*Configure GPIO pin Output Level */
  HAL_GPIO_WritePin(GPIOA, GPIO_PIN_0|GPIO_PIN_15, GPIO_PIN_RESET);

  /*Configure GPIO pin Output Level */
  HAL_GPIO_WritePin(GPIOB, GPIO_PIN_14|GPIO_PIN_15|GPIO_PIN_4|GPIO_PIN_5
                          |GPIO_PIN_6|GPIO_PIN_7|GPIO_PIN_8|GPIO_PIN_9, GPIO_PIN_RESET);

  /*Configure GPIO pin Output Level */
  HAL_GPIO_WritePin(GPIOH, GPIO_PIN_3, GPIO_PIN_RESET);

  /*Configure GPIO pins : PC0 PC1 PC2 PC4
                           PC5 PC6 PC7 PC8
                           PC9 PC10 PC11 PC12 */
  GPIO_InitStruct.Pin = GPIO_PIN_0|GPIO_PIN_1|GPIO_PIN_2|GPIO_PIN_4
                          |GPIO_PIN_5|GPIO_PIN_6|GPIO_PIN_7|GPIO_PIN_8
                          |GPIO_PIN_9|GPIO_PIN_10|GPIO_PIN_11|GPIO_PIN_12;
  GPIO_InitStruct.Mode = GPIO_MODE_OUTPUT_PP;
  GPIO_InitStruct.Pull = GPIO_NOPULL;
  GPIO_InitStruct.Speed = GPIO_SPEED_FREQ_LOW;
  HAL_GPIO_Init(GPIOC, &GPIO_InitStruct);

  /*Configure GPIO pins : PA0 PA15 */
  GPIO_InitStruct.Pin = GPIO_PIN_0|GPIO_PIN_15;
  GPIO_InitStruct.Mode = GPIO_MODE_OUTPUT_PP;
  GPIO_InitStruct.Pull = GPIO_NOPULL;
  GPIO_InitStruct.Speed = GPIO_SPEED_FREQ_LOW;
  HAL_GPIO_Init(GPIOA, &GPIO_InitStruct);

  /*Configure GPIO pins : PB1 PB2 */
  GPIO_InitStruct.Pin = GPIO_PIN_1|GPIO_PIN_2;
  GPIO_InitStruct.Mode = GPIO_MODE_IT_RISING;
  GPIO_InitStruct.Pull = GPIO_NOPULL;
  HAL_GPIO_Init(GPIOB, &GPIO_InitStruct);

  /*Configure GPIO pins : PB14 PB15 PB4 PB5
                           PB6 PB7 PB8 PB9 */
  GPIO_InitStruct.Pin = GPIO_PIN_14|GPIO_PIN_15|GPIO_PIN_4|GPIO_PIN_5
                          |GPIO_PIN_6|GPIO_PIN_7|GPIO_PIN_8|GPIO_PIN_9;
  GPIO_InitStruct.Mode = GPIO_MODE_OUTPUT_PP;
  GPIO_InitStruct.Pull = GPIO_NOPULL;
  GPIO_InitStruct.Speed = GPIO_SPEED_FREQ_LOW;
  HAL_GPIO_Init(GPIOB, &GPIO_InitStruct);

  /*Configure GPIO pin : PD2 */
  GPIO_InitStruct.Pin = GPIO_PIN_2;
  GPIO_InitStruct.Mode = GPIO_MODE_INPUT;
  GPIO_InitStruct.Pull = GPIO_NOPULL;
  HAL_GPIO_Init(GPIOD, &GPIO_InitStruct);

  /*Configure GPIO pin : PB3 */
  GPIO_InitStruct.Pin = GPIO_PIN_3;
  GPIO_InitStruct.Mode = GPIO_MODE_INPUT;
  GPIO_InitStruct.Pull = GPIO_NOPULL;
  HAL_GPIO_Init(GPIOB, &GPIO_InitStruct);

  /*Configure GPIO pin : PH3 */
  GPIO_InitStruct.Pin = GPIO_PIN_3;
  GPIO_InitStruct.Mode = GPIO_MODE_OUTPUT_PP;
  GPIO_InitStruct.Pull = GPIO_NOPULL;
  GPIO_InitStruct.Speed = GPIO_SPEED_FREQ_LOW;
  HAL_GPIO_Init(GPIOH, &GPIO_InitStruct);

  /* EXTI interrupt init*/
  HAL_NVIC_SetPriority(EXTI1_IRQn, 0, 0);
  HAL_NVIC_EnableIRQ(EXTI1_IRQn);

  HAL_NVIC_SetPriority(EXTI2_IRQn, 0, 0);
  HAL_NVIC_EnableIRQ(EXTI2_IRQn);

}

void Error_Handler(void)
{
  __disable_irq();
  while (1)
  {
  }
}
